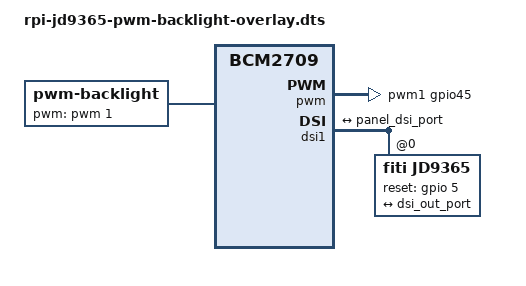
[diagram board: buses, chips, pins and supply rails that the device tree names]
/dts-v1/;
/plugin/;

/ {
    compatible = "brcm,bcm2835", "brcm,bcm2708", "brcm,bcm2709";

	fragment@0 {
		target = <&gpio>;
		__overlay__ {
			rpi_panel_pins: rpi_panel_pins {
				brcm,pins = <5>;
				brcm,function = <1>; /* out */
			};
		};
	};

	fragment@1 {
		target = <&pwm>;
		__overlay__ {
			pinctrl-names = "default";
			pinctrl-0 = <&pwm1_gpio45>;
			assigned-clock-rates = <3012000>;
			status = "okay";
		};
	};

	fragment@2 {
		target-path = "/soc";
		__overlay__ {
			backlight: backlight {
				compatible = "pwm-backlight";
				pwms = <&pwm 1 1000000 0>;
				brightness-levels = <0 25 50 75 100>;
				num-interpolated-steps = <25>;
				default-brightness-level = <50>;
				status = "okay";
			};
		};
	};

	fragment@3 {
		target = <&dsi1>;
		__overlay__ {
			#address-cells = <1>;
			#size-cells = <0>;
			status = "okay";

			port {
				dsi_out_port: endpoint {
					remote-endpoint = <&panel_dsi_port>;
				};
			};

			panel_jd9365: panel@0 {
				compatible = "fiti,jd9365";
				reg = <0>;
				label = "jd9365";
				vc4_dsi = <&dsi1>;
				reset-gpios = <&gpio 5 0>;
				port {
					panel_dsi_port: endpoint {
						remote-endpoint = <&dsi_out_port>;
					};
				};
			};
		};
	};
};
